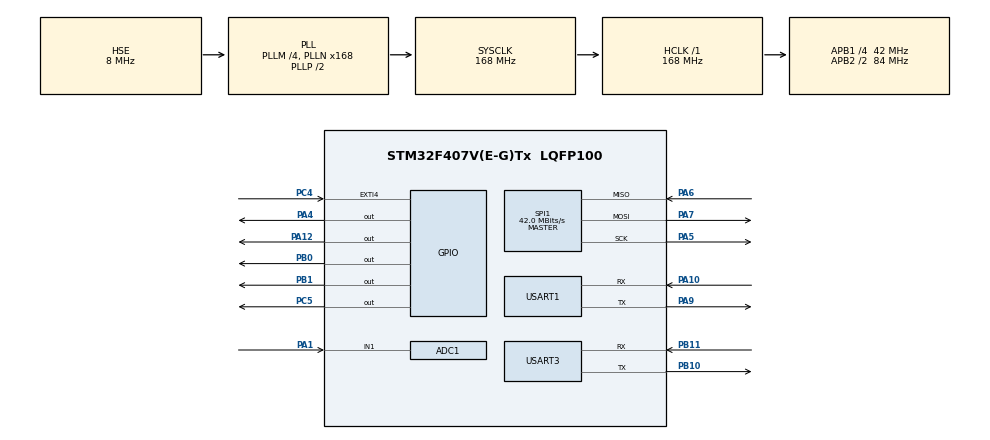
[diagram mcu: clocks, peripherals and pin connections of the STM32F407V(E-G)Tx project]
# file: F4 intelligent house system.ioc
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ADC1.Channel-3\#ChannelRegularConversion=ADC_CHANNEL_1
ADC1.NbrOfConversionFlag=1
ADC1.Rank-3\#ChannelRegularConversion=1
ADC1.SamplingTime-3\#ChannelRegularConversion=ADC_SAMPLETIME_3CYCLES
ADC1.master=1
FREERTOS.Tasks01=defaultTask,24,256,StartDefaultTask,Default,NULL,Dynamic,NULL,NULL
FREERTOS.configMINIMAL_STACK_SIZE=256
Mcu.Family=STM32F4
Mcu.Name=STM32F407V(E-G)Tx
Mcu.Package=LQFP100
NVIC.ADC_IRQn=true\:5\:0\:false\:false\:true\:true\:true\:true\:true
NVIC.PriorityGroup=NVIC_PRIORITYGROUP_4
NVIC.SPI1_IRQn=true\:5\:0\:false\:false\:true\:true\:true\:true\:true
NVIC.TIM4_IRQn=true\:15\:0\:false\:false\:true\:false\:false\:true\:true
NVIC.TimeBase=TIM4_IRQn
NVIC.TimeBaseIP=TIM4
NVIC.USART1_IRQn=true\:5\:0\:false\:false\:true\:true\:true\:true\:true
NVIC.USART3_IRQn=true\:5\:0\:false\:false\:true\:true\:true\:true\:true
PA0-WKUP.Mode=SYS_WakeUp0
PA0-WKUP.Signal=SYS_WKUP
PA1.Signal=ADCx_IN1
PA10.Mode=Asynchronous
PA10.Signal=USART1_RX
PA12.Signal=GPIO_Output
PA13.Mode=Serial_Wire
PA13.Signal=SYS_JTMS-SWDIO
PA14.Mode=Serial_Wire
PA14.Signal=SYS_JTCK-SWCLK
PA4.Signal=GPIO_Output
PA5.Mode=Full_Duplex_Master
PA5.Signal=SPI1_SCK
PA6.Mode=Full_Duplex_Master
PA6.Signal=SPI1_MISO
PA7.Mode=Full_Duplex_Master
PA7.Signal=SPI1_MOSI
PA9.Mode=Asynchronous
PA9.Signal=USART1_TX
PB0.Signal=GPIO_Output
PB1.GPIO_Speed=GPIO_SPEED_FREQ_HIGH
PB1.PinState=GPIO_PIN_SET
PB1.Signal=GPIO_Output
PB10.Mode=Asynchronous
PB10.Signal=USART3_TX
PB11.Mode=Asynchronous
PB11.Signal=USART3_RX
PC14-OSC32_IN.Mode=LSE-External-Oscillator
PC14-OSC32_IN.Signal=RCC_OSC32_IN
PC15-OSC32_OUT.Mode=LSE-External-Oscillator
PC15-OSC32_OUT.Signal=RCC_OSC32_OUT
PC4.Signal=GPXTI4
PC5.Signal=GPIO_Output
PH0-OSC_IN.Mode=HSE-External-Oscillator
PH0-OSC_IN.Signal=RCC_OSC_IN
PH1-OSC_OUT.Mode=HSE-External-Oscillator
PH1-OSC_OUT.Signal=RCC_OSC_OUT
ProjectManager.HeapSize=0x200
ProjectManager.StackSize=0x400
ProjectManager.TargetToolchain=MDK-ARM V5.32
RCC.48MHZClocksFreq_Value=84000000
RCC.AHBFreq_Value=168000000
RCC.APB1CLKDivider=RCC_HCLK_DIV4
RCC.APB1Freq_Value=42000000
RCC.APB1TimFreq_Value=84000000
RCC.APB2CLKDivider=RCC_HCLK_DIV2
RCC.APB2Freq_Value=84000000
RCC.APB2TimFreq_Value=168000000
RCC.CortexFreq_Value=168000000
RCC.HCLKFreq_Value=168000000
RCC.HSE_VALUE=8000000
RCC.HSI_VALUE=16000000
RCC.PLLM=4
RCC.PLLN=168
RCC.PLLSourceVirtual=RCC_PLLSOURCE_HSE
RCC.SYSCLKFreq_VALUE=168000000
RCC.SYSCLKSource=RCC_SYSCLKSOURCE_PLLCLK
RCC.VCOOutputFreq_Value=336000000
SH.ADCx_IN1.0=ADC1_IN1,IN1
SPI1.CRCCalculation=SPI_CRCCALCULATION_DISABLE
SPI1.CalculateBaudRate=42.0 MBits/s
SPI1.Direction=SPI_DIRECTION_2LINES
SPI1.Mode=SPI_MODE_MASTER
SPI1.VirtualType=VM_MASTER
USART1.VirtualMode=VM_ASYNC
USART3.VirtualMode=VM_ASYNC
VP_FREERTOS_VS_CMSIS_V2.Mode=CMSIS_V2
VP_SYS_VS_tim4.Mode=TIM4
VP_TIM5_VS_ClockSourceITR.Mode=TriggerSource_ITR0
VP_TIM5_VS_ControllerModeClock.Mode=Clock Mode
board=custom

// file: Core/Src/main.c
/* USER CODE BEGIN Header */
/**
  ******************************************************************************
  * @file           : main.c
  * @brief          : Main program body
  ******************************************************************************
  * @attention
  *
  * Copyright (c) 2024 STMicroelectronics.
  * All rights reserved.
  *
  * This software is licensed under terms that can be found in the LICENSE file
  * in the root directory of this software component.
  * If no LICENSE file comes with this software, it is provided AS-IS.
  *
  ******************************************************************************
  */
/* USER CODE END Header */
#include "main.h"
#include "cmsis_os.h"
#include "adc.h"
#include "spi.h"
#include "tim.h"
#include "usart.h"
#include "gpio.h"

/* USER CODE BEGIN PM */
ring_buffer test_buffer;
/* USER CODE END PM */

void SystemClock_Config(void);
void MX_FREERTOS_Init(void);

int main(void)
{

  /* MCU Configuration--------------------------------------------------------*/

  /* Reset of all peripherals, Initializes the Flash interface and the Systick. */
  HAL_Init();

  /* Configure the system clock */
  SystemClock_Config();

  /* Initialize all configured peripherals */
  MX_GPIO_Init();
  MX_TIM5_Init();
  MX_USART1_UART_Init();
  MX_USART3_UART_Init();
  MX_ADC1_Init();
  MX_SPI1_Init();
  /* USER CODE BEGIN 2 */
	EnableDebugIRQ();
	EnableUART3IRQ();
	Uart3_Lock_Init();
  ring_buffer_init(&test_buffer);

	ATInit();
	printf("Hello World!\r\n");
  /* USER CODE END 2 */

  /* Init scheduler */
  osKernelInitialize();

  /* Call init function for freertos objects (in cmsis_os2.c) */
  MX_FREERTOS_Init();

  /* Start scheduler */
  osKernelStart();

  /* We should never get here as control is now taken by the scheduler */

  /* Infinite loop */
  while (1)
  {

  }
}

void SystemClock_Config(void)
{
  RCC_OscInitTypeDef RCC_OscInitStruct = {0};
  RCC_ClkInitTypeDef RCC_ClkInitStruct = {0};

  /** Configure the main internal regulator output voltage
  */
  __HAL_RCC_PWR_CLK_ENABLE();
  __HAL_PWR_VOLTAGESCALING_CONFIG(PWR_REGULATOR_VOLTAGE_SCALE1);

  /** Initializes the RCC Oscillators according to the specified parameters
  * in the RCC_OscInitTypeDef structure.
  */
  RCC_OscInitStruct.OscillatorType = RCC_OSCILLATORTYPE_HSE;
  RCC_OscInitStruct.HSEState = RCC_HSE_ON;
  RCC_OscInitStruct.PLL.PLLState = RCC_PLL_ON;
  RCC_OscInitStruct.PLL.PLLSource = RCC_PLLSOURCE_HSE;
  RCC_OscInitStruct.PLL.PLLM = 4;
  RCC_OscInitStruct.PLL.PLLN = 168;
  RCC_OscInitStruct.PLL.PLLP = RCC_PLLP_DIV2;
  RCC_OscInitStruct.PLL.PLLQ = 4;
  if (HAL_RCC_OscConfig(&RCC_OscInitStruct) != HAL_OK)
  {
    Error_Handler();
  }

  /** Initializes the CPU, AHB and APB buses clocks
  */
  RCC_ClkInitStruct.ClockType = RCC_CLOCKTYPE_HCLK|RCC_CLOCKTYPE_SYSCLK
                              |RCC_CLOCKTYPE_PCLK1|RCC_CLOCKTYPE_PCLK2;
  RCC_ClkInitStruct.SYSCLKSource = RCC_SYSCLKSOURCE_PLLCLK;
  RCC_ClkInitStruct.AHBCLKDivider = RCC_SYSCLK_DIV1;
  RCC_ClkInitStruct.APB1CLKDivider = RCC_HCLK_DIV4;
  RCC_ClkInitStruct.APB2CLKDivider = RCC_HCLK_DIV2;

  if (HAL_RCC_ClockConfig(&RCC_ClkInitStruct, FLASH_LATENCY_5) != HAL_OK)
  {
    Error_Handler();
  }
}

void HAL_TIM_PeriodElapsedCallback(TIM_HandleTypeDef *htim)
{
  if (htim->Instance == TIM4) {
    HAL_IncTick();
  }
}

void Error_Handler(void)
{
  __disable_irq();
  while (1)
  {
  }
}

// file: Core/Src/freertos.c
/* USER CODE BEGIN Header */
/**
  ******************************************************************************
  * File Name          : freertos.c
  * Description        : Code for freertos applications
  ******************************************************************************
  * @attention
  *
  * Copyright (c) 2024 STMicroelectronics.
  * All rights reserved.
  *
  * This software is licensed under terms that can be found in the LICENSE file
  * in the root directory of this software component.
  * If no LICENSE file comes with this software, it is provided AS-IS.
  *
  ******************************************************************************
  */
/* USER CODE END Header */

#include "FreeRTOS.h"
#include "task.h"
#include "main.h"
#include "cmsis_os.h"

/* USER CODE BEGIN Includes */
#include "ATcommand.h"
/* USER CODE END Includes */

/* Definitions for defaultTask */
osThreadId_t defaultTaskHandle;
const osThreadAttr_t defaultTask_attributes = {
  .name = "defaultTask",
  .stack_size = 256 * 4,
  .priority = (osPriority_t) osPriorityNormal,
};

void StartDefaultTask(void *argument);

void MX_FREERTOS_Init(void); /* (MISRA C 2004 rule 8.1) */

void MX_FREERTOS_Init(void) {

  /* Create the thread(s) */
  /* creation of defaultTask */
  defaultTaskHandle = osThreadNew(StartDefaultTask, NULL, &defaultTask_attributes);

  /* USER CODE BEGIN RTOS_THREADS */
  /* add threads, ... */
	osThreadNew(AT_RecvParse, NULL, &defaultTask_attributes);
	osThreadNew(MQTT_Client_Task, NULL, &defaultTask_attributes);
  /* USER CODE END RTOS_THREADS */

}

void StartDefaultTask(void *argument)
{
  /* USER CODE BEGIN StartDefaultTask */
	printf("StartDefaultTask\r\n");
  /* Infinite loop */
  for(;;)
  {
    osDelay(1);
  }
  /* USER CODE END StartDefaultTask */
}
